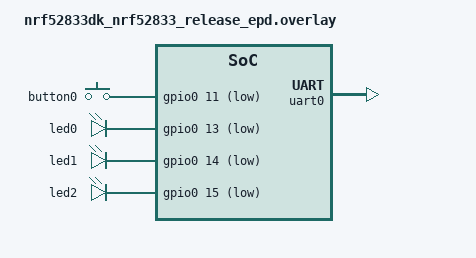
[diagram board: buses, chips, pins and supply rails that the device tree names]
#include "waveshare_epaper_HINK-E0213-G01.dtsi"

&uart0 {
	status = "okay";
};
&i2c0 {
	status = "disabled";
};
&uart1 {
	status = "disabled";
};
&spi1 {
	status = "disabled";
};
&adc {
	status = "disabled";
};
&usbd {
	status = "disabled";
};

&button0 {
	gpios = <&gpio0 11 (GPIO_ACTIVE_LOW | GPIO_PULL_UP)>;
};

&led0 {
	gpios = <&gpio0 13 GPIO_ACTIVE_LOW>;
};

&led1 {
	gpios = <&gpio0 14 GPIO_ACTIVE_LOW>;
};

&led2 {
	gpios = <&gpio0 15 GPIO_ACTIVE_LOW>;
};
